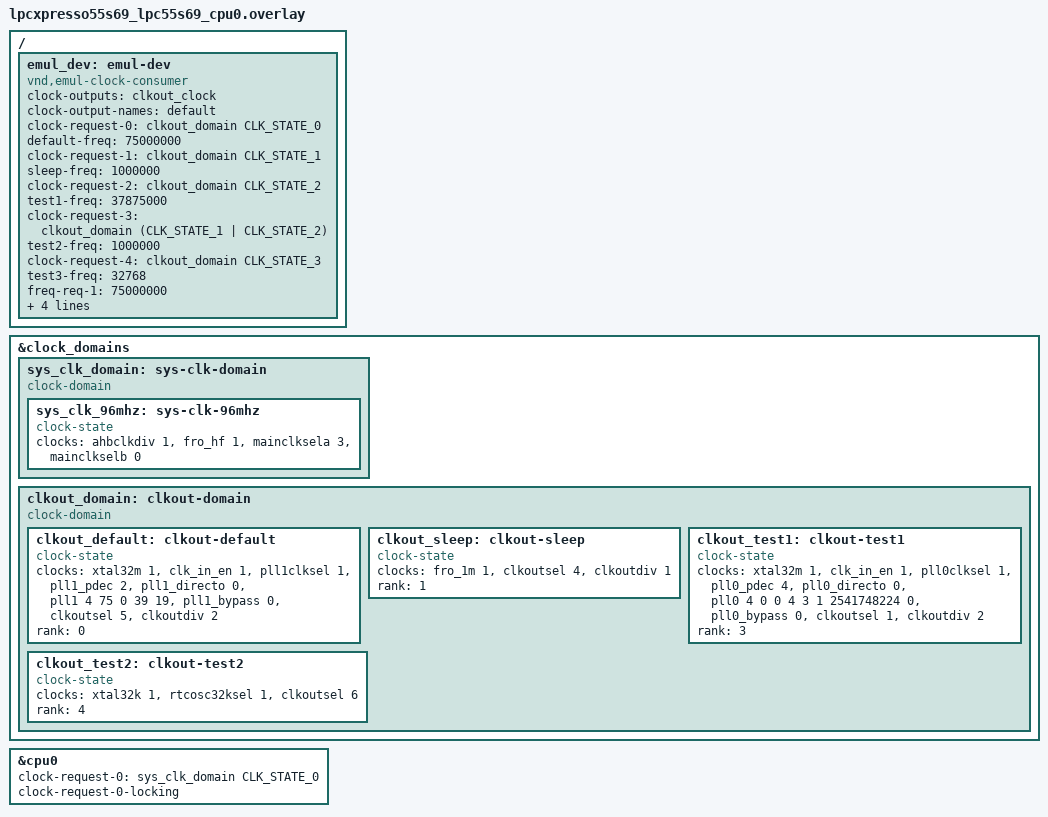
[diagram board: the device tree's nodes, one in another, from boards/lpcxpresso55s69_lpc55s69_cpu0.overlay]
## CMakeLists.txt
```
# SPDX-License-Identifier: Apache-2.0

cmake_minimum_required(VERSION 3.20.0)

find_package(Zephyr REQUIRED HINTS $ENV{ZEPHYR_BASE})
project(clock_management_hw)

file(GLOB app_sources src/*.c)
target_sources(app PRIVATE ${app_sources})
```

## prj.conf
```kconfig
CONFIG_ZTEST=y
CONFIG_CLOCK_MANAGEMENT=y
CONFIG_CLOCK_MANAGEMENT_RUNTIME=y
CONFIG_CLOCK_MANAGEMENT_SET_RATE=y
CONFIG_ZTEST_STACK_SIZE=2048
CONFIG_CLOCK_MANAGEMENT_KEEP_SLEEP_STATE=y
```

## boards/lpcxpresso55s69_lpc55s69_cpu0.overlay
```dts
/*
 * Copyright 2024 NXP
 * Copyright (c) 2026, Analog Devices Inc
 *
 * SPDX-License-Identifier: Apache-2.0
 */

#include <zephyr/dt-bindings/clock-management/clock-management.h>

&clock_domains {
	sys_clk_domain: sys-clk-domain {
		/delete-node/ sys_clk_144mhz;
		compatible = "clock-domain";
		/* Clock CPU from FROHF, since we will use the PLLs within our testcases */
		sys_clk_96mhz: sys-clk-96mhz {
			compatible = "clock-state";
			clocks = <&ahbclkdiv 1 &fro_hf 1 &mainclksela 3 &mainclkselb 0>;
		};
	};

	/* Define clock states for clockout clock */
	clkout_domain: clkout-domain {
		compatible = "clock-domain";
		#clock-state-cells = <1>;
		clkout_default: clkout-default {
			compatible = "clock-state";
			/* Enable PLL1 and switch clkout to use it */
			clocks = <&xtal32m 1 &clk_in_en 1 &pll1clksel 1 &pll1_pdec 2
				  &pll1_directo 0 &pll1 4 75 0 39 19
				  &pll1_bypass 0 &clkoutsel 5 &clkoutdiv 2>;
			rank = <0>;
		};

		clkout_sleep: clkout-sleep {
			compatible = "clock-state";
			clocks = <&fro_1m 1 &clkoutsel 4 &clkoutdiv 1>;
			rank = <1>;
		};

		clkout_test1: clkout-test1 {
			compatible = "clock-state";
			/* Configure PLL0 and switch clkout to use it */
			clocks = <&xtal32m 1 &clk_in_en 1 &pll0clksel 1 &pll0_pdec 4
				  &pll0_directo 0 &pll0 4 0 0 4 3 1 2541748224 0
				  &pll0_bypass 0 &clkoutsel 1 &clkoutdiv 2>;
			rank = <3>;
		};

		clkout_test2: clkout-test2 {
			compatible = "clock-state";
			/* Use RTC */
			clocks = <&xtal32k 1 &rtcosc32ksel 1 &clkoutsel 6>;
			rank = <4>;
		};
	};
};

&cpu0 {
	clock-request-0 = <&sys_clk_domain CLK_STATE_0>;
	clock-request-0-locking;
};

/ {
	emul_dev: emul-dev {
		compatible = "vnd,emul-clock-consumer";
		clock-outputs = <&clkout_clock>;
		clock-output-names = "default";
		clock-request-0 = <&clkout_domain CLK_STATE_0>;
		default-freq = <75000000>;
		clock-request-1 = <&clkout_domain CLK_STATE_1>;
		sleep-freq = <1000000>;
		clock-request-2 = <&clkout_domain CLK_STATE_2>;
		test1-freq = <37875000>;
		clock-request-3 = <&clkout_domain (CLK_STATE_1 | CLK_STATE_2)>;
		test2-freq = <1000000>;
		clock-request-4 = <&clkout_domain CLK_STATE_3>;
		test3-freq = <32768>;
		freq-req-1 = <75000000>;
		freq-req-2 = <43252000>;
		freq-req-3 = <32768>;
		clock-request-names = "default", "sleep", "test1",
				      "test2", "test3";
	};
};
```

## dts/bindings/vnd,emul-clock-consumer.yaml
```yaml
# Copyright 2024 NXP
#
# SPDX-License-Identifier: Apache-2.0

description: |
  Binding for emulated clock consumer device. This device is used in testing
  to verify that clock states are applied as expected.

compatible: "vnd,emul-clock-consumer"

include: [clock-device.yaml]

properties:
  default-freq:
    type: int
    required: true
    description: |
      Frequency this consumer expects to read when applying default clock
      management state

  sleep-freq:
    type: int
    required: true
    description: |
      Frequency this consumer expects to read when applying sleep clock
      management state

  test1-freq:
    type: int
    required: true
    description: |
      Frequency this consumer expects to read when applying test1 clock
      management state

  test2-freq:
    type: int
    required: true
    description: |
      Frequency this consumer expects to read when applying test2 clock
      management state

  test3-freq:
    type: int
    required: true
    description: |
      Frequency this consumer expects to read when applying test3 clock
      management state

  freq-req-1:
    type: int
    required: true
    description: |
     First frequency this consumer will request from the clock subsystem

  freq-req-2:
    type: int
    required: true
    description: |
     Second frequency this consumer will request from the clock subsystem

  freq-req-3:
    type: int
    required: true
    description: |
     Third frequency this consumer will request from the clock subsystem
```

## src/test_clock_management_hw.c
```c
/*
 * Copyright 2024 NXP
 *
 * SPDX-License-Identifier: Apache-2.0
 */
#include <zephyr/ztest.h>
#include <zephyr/drivers/clock_management.h>
#include <zephyr/logging/log.h>
LOG_MODULE_REGISTER(test);

#define CONSUMER_NODE DT_NODELABEL(emul_dev)

/*
 * Custom request identifiers for the names used in clock-request-names.
 * These must be defined before CLOCK_MANAGEMENT_DT_DEFINE is expanded.
 */
#define CLOCK_MANAGEMENT_STATE_TEST1 (CLOCK_MANAGEMENT_STATE_PRIV_START)
#define CLOCK_MANAGEMENT_STATE_TEST2 (CLOCK_MANAGEMENT_STATE_PRIV_START + 1)
#define CLOCK_MANAGEMENT_STATE_TEST3 (CLOCK_MANAGEMENT_STATE_PRIV_START + 2)

CLOCK_MANAGEMENT_DT_DEFINE(CONSUMER_NODE);

/* Get references to each clock management state and output */
static const struct clock_management_data *data =
	CLOCK_MANAGEMENT_DT_GET(CONSUMER_NODE);
static clock_output_t consumer_out =
	CLOCK_MANAGEMENT_DT_GET_OUTPUT(CONSUMER_NODE);

static clock_request_t default_request = CLOCK_MANAGEMENT_STATE_DEFAULT;
static clock_request_t sleep_request = CLOCK_MANAGEMENT_STATE_SLEEP;
static clock_request_t test1_request = CLOCK_MANAGEMENT_STATE_TEST1;
static clock_request_t test2_request = CLOCK_MANAGEMENT_STATE_TEST2;
static clock_request_t test3_request = CLOCK_MANAGEMENT_STATE_TEST3;

void request_clock_state(clock_request_t request, const char *req_name,
		       int expected_rate)
{
	int ret;

	/* Apply clock request, verify frequencies */
	TC_PRINT("Try to apply %s clock request\n", req_name);

	ret = clock_management_request_state(data, request);
	zassert_equal(ret, 0,
		      "Failed to apply %s clock management state", req_name);

	/* Check rate */
	ret = clock_management_get_rate(data, consumer_out);
	TC_PRINT("Consumer %s clock rate: %d\n", req_name, ret);
	zassert_equal(ret, expected_rate,
		      "Consumer has invalid %s clock rate", req_name);
}

void request_clock_frequency(clock_freq_t freq, const char *req_name)
{
	int ret;

	TC_PRINT("Requesting frequency %d for %s\n", freq, req_name);

	ret = clock_management_req_rate(data, consumer_out, freq);
	zassert_equal(ret, freq, "Consumer did not realize requested frequency");
}

ZTEST(clock_management_hw, test_apply_states)
{
	request_clock_state(default_request, "default",
			  DT_PROP(CONSUMER_NODE, default_freq));
	request_clock_state(sleep_request, "sleep",
			  DT_PROP(CONSUMER_NODE, sleep_freq));
	request_clock_state(test1_request, "test1",
			  DT_PROP(CONSUMER_NODE, test1_freq));
	request_clock_state(test2_request, "test2",
			  DT_PROP(CONSUMER_NODE, test2_freq));
	request_clock_state(test3_request, "test3",
			  DT_PROP(CONSUMER_NODE, test3_freq));
}

ZTEST(clock_management_hw, test_freq_req)
{
	clock_freq_t req1 = DT_PROP(CONSUMER_NODE, freq_req_1);
	clock_freq_t req2 = DT_PROP(CONSUMER_NODE, freq_req_2);
	clock_freq_t req3 = DT_PROP(CONSUMER_NODE, freq_req_3);

	request_clock_frequency(req1, "req1");
	request_clock_frequency(req2, "req2");
	request_clock_frequency(req3, "req3");
}

ZTEST_SUITE(clock_management_hw, NULL, NULL, NULL, NULL, NULL);
```
